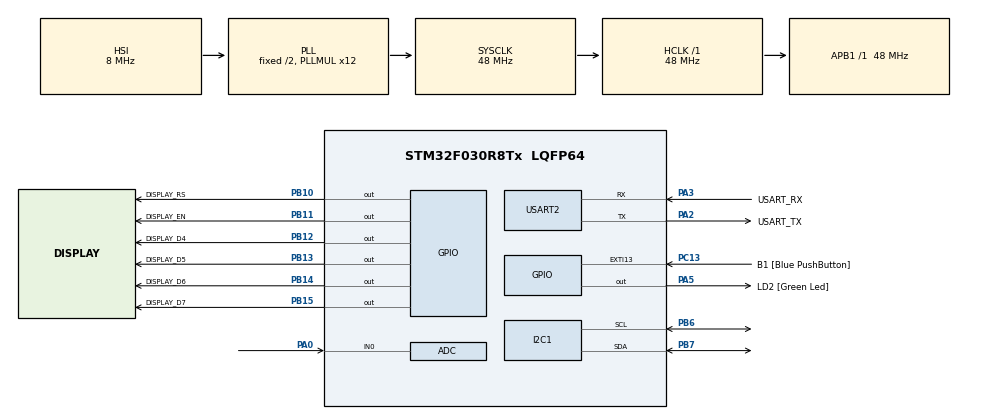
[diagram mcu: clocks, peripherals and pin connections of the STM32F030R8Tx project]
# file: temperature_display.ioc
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Mcu.Family=STM32F0
PC15-OSC32_OUT.Mode=LSE-External-Oscillator
PA2.GPIO_PuPd=GPIO_NOPULL
PC13.Signal=GPXTI13
PB14.GPIO_Label=DISPLAY_D6
PA14.GPIO_Label=TCK
PA3.GPIO_PuPd=GPIO_NOPULL
PA2.GPIO_Speed=GPIO_SPEED_FREQ_LOW
VP_TIM6_VS_ClockSourceINT.Mode=Enable_Timer
PB11.GPIO_Label=DISPLAY_EN
PC13.GPIO_Label=B1 [Blue PushButton]
PC14-OSC32_IN.Signal=RCC_OSC32_IN
PB13.GPIO_Label=DISPLAY_D5
PB11.Signal=GPIO_Output
PA3.GPIO_Speed=GPIO_SPEED_FREQ_LOW
PB13.Signal=GPIO_Output
PB15.Signal=GPIO_Output
RCC.SYSCLKSource=RCC_SYSCLKSOURCE_PLLCLK
ProjectManager.StackSize=0x400
NVIC.TIM6_IRQn=true\:0\:0\:false\:false\:true\:true\:true
PA3.Mode=Asynchronous
PA13.Signal=SYS_SWDIO
ProjectManager.TargetToolchain=STM32CubeIDE
PB10.GPIO_Label=DISPLAY_RS
PA3.GPIO_Mode=GPIO_MODE_AF_PP
RCC.HCLKFreq_Value=48000000
PB6.Signal=I2C1_SCL
PB6.Mode=I2C
PC15-OSC32_OUT.Signal=RCC_OSC32_OUT
RCC.AHBFreq_Value=48000000
PF0-OSC_IN.Mode=HSE-External-Clock-Source
PB10.Signal=GPIO_Output
PB14.Signal=GPIO_Output
PA5.Signal=GPIO_Output
board=NUCLEO-F030R8
USART2.VirtualMode-Asynchronous=VM_ASYNC
RCC.PLLMUL=RCC_PLL_MUL12
PB12.GPIO_Label=DISPLAY_D4
PC14-OSC32_IN.Mode=LSE-External-Oscillator
PB15.GPIO_Label=DISPLAY_D7
PA14.Mode=Serial_Wire
PA5.GPIO_PuPd=GPIO_NOPULL
PA0.Mode=IN0
PB7.Signal=I2C1_SDA
PA13.Mode=Serial_Wire
Mcu.Name=STM32F030R8Tx
PA2.Signal=USART2_TX
PA13.GPIO_Label=TMS
PA0.Signal=ADC_IN0
RCC.SYSCLKFreq_VALUE=48000000
Mcu.Package=LQFP64
PA5.GPIO_Label=LD2 [Green Led]
PC13.GPIO_ModeDefaultEXTI=GPIO_MODE_IT_FALLING
PA2.GPIO_Label=USART_TX
PB7.Mode=I2C
PA14.Signal=SYS_SWCLK
ProjectManager.HeapSize=0x200
PA5.GPIO_Speed=GPIO_SPEED_FREQ_LOW
RCC.APB1TimFreq_Value=48000000
PA2.Mode=Asynchronous
PF0-OSC_IN.Signal=RCC_OSC_IN
RCC.APB1Freq_Value=48000000
PA5.GPIO_Mode=GPIO_MODE_OUTPUT_PP
PB12.Signal=GPIO_Output
PF1-OSC_OUT.Signal=RCC_OSC_OUT
PA3.GPIO_Label=USART_RX
PA3.Signal=USART2_RX
PA2.GPIO_Mode=GPIO_MODE_AF_PP

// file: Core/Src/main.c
/* USER CODE BEGIN Header */
/**
  ******************************************************************************
  * @file           : main.c
  * @brief          : Main program body
  ******************************************************************************
  * @attention
  *
  * <h2><center>&copy; Copyright (c) 2022 STMicroelectronics.
  * All rights reserved.</center></h2>
  *
  * This software component is licensed by ST under Ultimate Liberty license
  * SLA0044, the "License"; You may not use this file except in compliance with
  * the License. You may obtain a copy of the License at:
  *                             www.st.com/SLA0044
  *
  ******************************************************************************
  */
/* USER CODE END Header */
#include "main.h"

/* USER CODE BEGIN Includes */

#include "thermistor.h"
#include "render.h"
#include <iso646.h>

/* USER CODE END Includes */

I2C_HandleTypeDef hi2c1;

TIM_HandleTypeDef htim6;

UART_HandleTypeDef huart2;

void SystemClock_Config(void);
static void MX_GPIO_Init(void);
static void MX_USART2_UART_Init(void);
static void MX_I2C1_Init(void);
static void MX_TIM6_Init(void);
static void MX_ADC_Init(void);

int main(void)
{

  /* MCU Configuration--------------------------------------------------------*/

  /* Reset of all peripherals, Initializes the Flash interface and the Systick. */
  HAL_Init();

  /* Configure the system clock */
  SystemClock_Config();

  /* Initialize all configured peripherals */
  MX_GPIO_Init();
  MX_USART2_UART_Init();
  MX_I2C1_Init();
  MX_TIM6_Init();
  MX_ADC_Init();
  /* USER CODE BEGIN 2 */

  thermistor_init();
  render_init();

  /* USER CODE END 2 */

  /* Infinite loop */
  /* USER CODE BEGIN WHILE */
  while (1)
  {
	  thermistor_begin_reading();
	  while(not thermistor_reading_complete());
	  render_values(thermistor_get_reading(), thermistor_get_units());

	  HAL_Delay(1000);
	  // todo sleep?
	  // todo - add wdt?

    /* USER CODE END WHILE */

  }
}

void SystemClock_Config(void)
{
  RCC_OscInitTypeDef RCC_OscInitStruct = {0};
  RCC_ClkInitTypeDef RCC_ClkInitStruct = {0};
  RCC_PeriphCLKInitTypeDef PeriphClkInit = {0};

  /** Initializes the RCC Oscillators according to the specified parameters
  * in the RCC_OscInitTypeDef structure.
  */
  RCC_OscInitStruct.OscillatorType = RCC_OSCILLATORTYPE_HSI|RCC_OSCILLATORTYPE_HSI14;
  RCC_OscInitStruct.HSIState = RCC_HSI_ON;
  RCC_OscInitStruct.HSI14State = RCC_HSI14_ON;
  RCC_OscInitStruct.HSICalibrationValue = RCC_HSICALIBRATION_DEFAULT;
  RCC_OscInitStruct.HSI14CalibrationValue = 16;
  RCC_OscInitStruct.PLL.PLLState = RCC_PLL_ON;
  RCC_OscInitStruct.PLL.PLLSource = RCC_PLLSOURCE_HSI;
  RCC_OscInitStruct.PLL.PLLMUL = RCC_PLL_MUL12;
  RCC_OscInitStruct.PLL.PREDIV = RCC_PREDIV_DIV1;
  if (HAL_RCC_OscConfig(&RCC_OscInitStruct) != HAL_OK)
  {
    Error_Handler();
  }
  /** Initializes the CPU, AHB and APB buses clocks
  */
  RCC_ClkInitStruct.ClockType = RCC_CLOCKTYPE_HCLK|RCC_CLOCKTYPE_SYSCLK
                              |RCC_CLOCKTYPE_PCLK1;
  RCC_ClkInitStruct.SYSCLKSource = RCC_SYSCLKSOURCE_PLLCLK;
  RCC_ClkInitStruct.AHBCLKDivider = RCC_SYSCLK_DIV1;
  RCC_ClkInitStruct.APB1CLKDivider = RCC_HCLK_DIV1;

  if (HAL_RCC_ClockConfig(&RCC_ClkInitStruct, FLASH_LATENCY_1) != HAL_OK)
  {
    Error_Handler();
  }
  PeriphClkInit.PeriphClockSelection = RCC_PERIPHCLK_I2C1;
  PeriphClkInit.I2c1ClockSelection = RCC_I2C1CLKSOURCE_HSI;
  if (HAL_RCCEx_PeriphCLKConfig(&PeriphClkInit) != HAL_OK)
  {
    Error_Handler();
  }
}

static void MX_ADC_Init(void)
{

  LL_ADC_InitTypeDef ADC_InitStruct = {0};
  LL_ADC_REG_InitTypeDef ADC_REG_InitStruct = {0};

  LL_GPIO_InitTypeDef GPIO_InitStruct = {0};

  /* Peripheral clock enable */
  LL_APB1_GRP2_EnableClock(LL_APB1_GRP2_PERIPH_ADC1);

  LL_AHB1_GRP1_EnableClock(LL_AHB1_GRP1_PERIPH_GPIOA);
  /**ADC GPIO Configuration
  PA0   ------> ADC_IN0
  */
  GPIO_InitStruct.Pin = LL_GPIO_PIN_0;
  GPIO_InitStruct.Mode = LL_GPIO_MODE_ANALOG;
  GPIO_InitStruct.Pull = LL_GPIO_PULL_NO;
  LL_GPIO_Init(GPIOA, &GPIO_InitStruct);

  /** Configure Regular Channel
  */
  LL_ADC_REG_SetSequencerChAdd(ADC1, LL_ADC_CHANNEL_0);
  /** Configure the global features of the ADC (Clock, Resolution, Data Alignment and number of conversion)
  */
  ADC_InitStruct.Clock = LL_ADC_CLOCK_ASYNC;
  ADC_InitStruct.Resolution = LL_ADC_RESOLUTION_12B;
  ADC_InitStruct.DataAlignment = LL_ADC_DATA_ALIGN_RIGHT;
  ADC_InitStruct.LowPowerMode = LL_ADC_LP_MODE_NONE;
  LL_ADC_Init(ADC1, &ADC_InitStruct);
  ADC_REG_InitStruct.TriggerSource = LL_ADC_REG_TRIG_SOFTWARE;
  ADC_REG_InitStruct.SequencerDiscont = LL_ADC_REG_SEQ_DISCONT_DISABLE;
  ADC_REG_InitStruct.ContinuousMode = LL_ADC_REG_CONV_SINGLE;
  ADC_REG_InitStruct.DMATransfer = LL_ADC_REG_DMA_TRANSFER_LIMITED;
  ADC_REG_InitStruct.Overrun = LL_ADC_REG_OVR_DATA_PRESERVED;
  LL_ADC_REG_Init(ADC1, &ADC_REG_InitStruct);
  LL_ADC_REG_SetSequencerScanDirection(ADC1, LL_ADC_REG_SEQ_SCAN_DIR_FORWARD);
  LL_ADC_SetSamplingTimeCommonChannels(ADC1, LL_ADC_SAMPLINGTIME_1CYCLE_5);

}

static void MX_I2C1_Init(void)
{

  hi2c1.Instance = I2C1;
  hi2c1.Init.Timing = 0x2000090E;
  hi2c1.Init.OwnAddress1 = 0;
  hi2c1.Init.AddressingMode = I2C_ADDRESSINGMODE_7BIT;
  hi2c1.Init.DualAddressMode = I2C_DUALADDRESS_DISABLE;
  hi2c1.Init.OwnAddress2 = 0;
  hi2c1.Init.OwnAddress2Masks = I2C_OA2_NOMASK;
  hi2c1.Init.GeneralCallMode = I2C_GENERALCALL_DISABLE;
  hi2c1.Init.NoStretchMode = I2C_NOSTRETCH_DISABLE;
  if (HAL_I2C_Init(&hi2c1) != HAL_OK)
  {
    Error_Handler();
  }
  /** Configure Analogue filter
  */
  if (HAL_I2CEx_ConfigAnalogFilter(&hi2c1, I2C_ANALOGFILTER_ENABLE) != HAL_OK)
  {
    Error_Handler();
  }
  /** Configure Digital filter
  */
  if (HAL_I2CEx_ConfigDigitalFilter(&hi2c1, 0) != HAL_OK)
  {
    Error_Handler();
  }

}

static void MX_TIM6_Init(void)
{

  htim6.Instance = TIM6;
  htim6.Init.Prescaler = 0;
  htim6.Init.CounterMode = TIM_COUNTERMODE_UP;
  htim6.Init.Period = 65535;
  htim6.Init.AutoReloadPreload = TIM_AUTORELOAD_PRELOAD_DISABLE;
  if (HAL_TIM_Base_Init(&htim6) != HAL_OK)
  {
    Error_Handler();
  }

}

static void MX_USART2_UART_Init(void)
{

  huart2.Instance = USART2;
  huart2.Init.BaudRate = 38400;
  huart2.Init.WordLength = UART_WORDLENGTH_8B;
  huart2.Init.StopBits = UART_STOPBITS_1;
  huart2.Init.Parity = UART_PARITY_NONE;
  huart2.Init.Mode = UART_MODE_TX_RX;
  huart2.Init.HwFlowCtl = UART_HWCONTROL_NONE;
  huart2.Init.OverSampling = UART_OVERSAMPLING_16;
  huart2.Init.OneBitSampling = UART_ONE_BIT_SAMPLE_DISABLE;
  huart2.AdvancedInit.AdvFeatureInit = UART_ADVFEATURE_NO_INIT;
  if (HAL_UART_Init(&huart2) != HAL_OK)
  {
    Error_Handler();
  }

}

static void MX_GPIO_Init(void)
{
  GPIO_InitTypeDef GPIO_InitStruct = {0};

  /* GPIO Ports Clock Enable */
  __HAL_RCC_GPIOC_CLK_ENABLE();
  __HAL_RCC_GPIOF_CLK_ENABLE();
  __HAL_RCC_GPIOA_CLK_ENABLE();
  __HAL_RCC_GPIOB_CLK_ENABLE();

  /*Configure GPIO pin Output Level */
  HAL_GPIO_WritePin(LD2_GPIO_Port, LD2_Pin, GPIO_PIN_RESET);

  /*Configure GPIO pin Output Level */
  HAL_GPIO_WritePin(GPIOB, DISPLAY_RS_Pin|DISPLAY_EN_Pin|DISPLAY_D4_Pin|DISPLAY_D5_Pin
                          |DISPLAY_D6_Pin|DISPLAY_D7_Pin, GPIO_PIN_RESET);

  /*Configure GPIO pin : B1_Pin */
  GPIO_InitStruct.Pin = B1_Pin;
  GPIO_InitStruct.Mode = GPIO_MODE_IT_FALLING;
  GPIO_InitStruct.Pull = GPIO_NOPULL;
  HAL_GPIO_Init(B1_GPIO_Port, &GPIO_InitStruct);

  /*Configure GPIO pin : LD2_Pin */
  GPIO_InitStruct.Pin = LD2_Pin;
  GPIO_InitStruct.Mode = GPIO_MODE_OUTPUT_PP;
  GPIO_InitStruct.Pull = GPIO_NOPULL;
  GPIO_InitStruct.Speed = GPIO_SPEED_FREQ_LOW;
  HAL_GPIO_Init(LD2_GPIO_Port, &GPIO_InitStruct);

  /*Configure GPIO pins : DISPLAY_RS_Pin DISPLAY_EN_Pin DISPLAY_D4_Pin DISPLAY_D5_Pin
                           DISPLAY_D6_Pin DISPLAY_D7_Pin */
  GPIO_InitStruct.Pin = DISPLAY_RS_Pin|DISPLAY_EN_Pin|DISPLAY_D4_Pin|DISPLAY_D5_Pin
                          |DISPLAY_D6_Pin|DISPLAY_D7_Pin;
  GPIO_InitStruct.Mode = GPIO_MODE_OUTPUT_PP;
  GPIO_InitStruct.Pull = GPIO_NOPULL;
  GPIO_InitStruct.Speed = GPIO_SPEED_FREQ_LOW;
  HAL_GPIO_Init(GPIOB, &GPIO_InitStruct);

}

void Error_Handler(void)
{
  __disable_irq();
  while (1)
  {
  }
}

/************************ (C) COPYRIGHT STMicroelectronics *****END OF FILE****/
